AUTOSAR XML (schema 4-3-0)
package /Comp_FDC_ARPkg
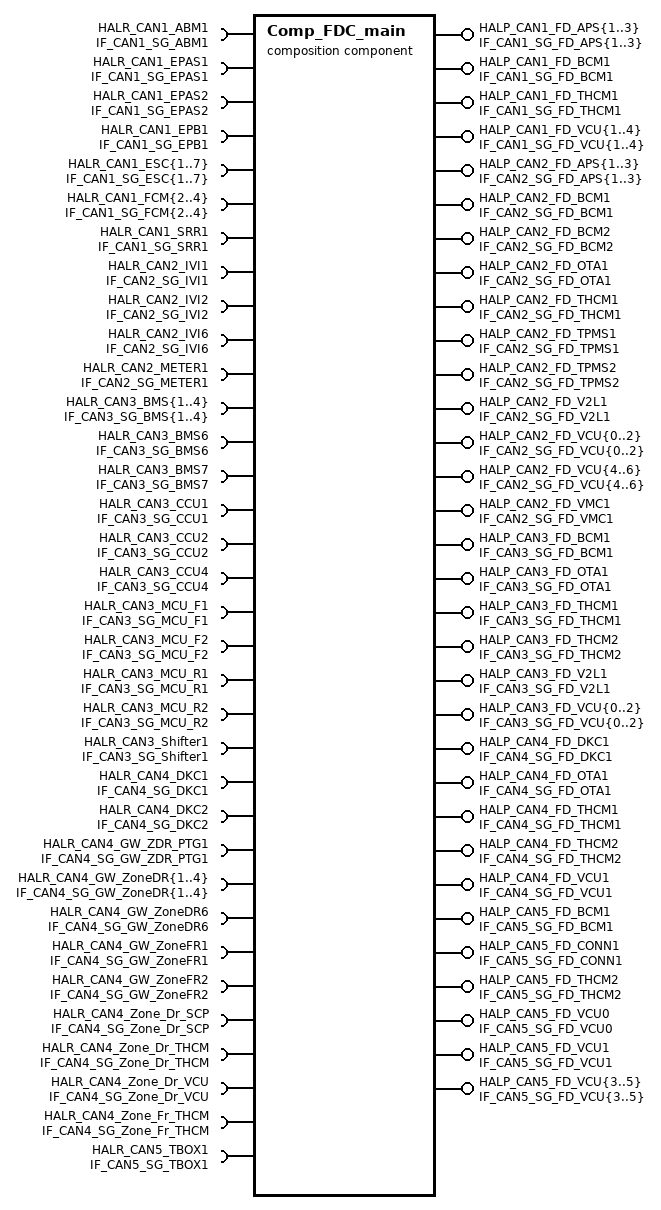
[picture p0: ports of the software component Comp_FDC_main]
  composition sw component type Comp_FDC_main
    47 x provide port:
      HALP_CAN1_FD_APS{1..3}: nonqueued-sender-com-spec{data-element=CAN1_SG_FD_APS{1..3}, handle-out-of-range=DEFAULT, init-value=constant-reference=Init_CAN1_SG_FD_APS{1..3}}, provided-interface=IF_CAN1_SG_FD_APS{1..3}
      HALP_CAN1_FD_BCM1: nonqueued-sender-com-spec{data-element=CAN1_SG_FD_BCM1, handle-out-of-range=DEFAULT, init-value=constant-reference=Init_CAN1_SG_FD_BCM1}, provided-interface=IF_CAN1_SG_FD_BCM1
      HALP_CAN1_FD_THCM1: nonqueued-sender-com-spec{data-element=CAN1_SG_FD_THCM1, handle-out-of-range=DEFAULT, init-value=constant-reference=Init_CAN1_SG_FD_THCM1}, provided-interface=IF_CAN1_SG_FD_THCM1
      HALP_CAN1_FD_VCU{1..4}: nonqueued-sender-com-spec{data-element=CAN1_SG_FD_VCU{1..4}, handle-out-of-range=DEFAULT, init-value=constant-reference=Init_CAN1_SG_FD_VCU{1..4}}, provided-interface=IF_CAN1_SG_FD_VCU{1..4}
      HALP_CAN2_FD_APS{1..3}: nonqueued-sender-com-spec{data-element=CAN2_SG_FD_APS{1..3}, handle-out-of-range=DEFAULT, init-value=constant-reference=Init_CAN2_SG_FD_APS{1..3}}, provided-interface=IF_CAN2_SG_FD_APS{1..3}
      HALP_CAN2_FD_BCM1: nonqueued-sender-com-spec{data-element=CAN2_SG_FD_BCM1, handle-out-of-range=DEFAULT, init-value=constant-reference=Init_CAN2_SG_FD_BCM1}, provided-interface=IF_CAN2_SG_FD_BCM1
      HALP_CAN2_FD_BCM2: nonqueued-sender-com-spec{data-element=CAN2_SG_FD_BCM2, handle-out-of-range=DEFAULT, init-value=constant-reference=Init_CAN2_SG_FD_BCM2}, provided-interface=IF_CAN2_SG_FD_BCM2
      HALP_CAN2_FD_OTA1: nonqueued-sender-com-spec{data-element=CAN2_SG_FD_OTA1, handle-out-of-range=DEFAULT, init-value=constant-reference=Init_CAN2_SG_FD_OTA1}, provided-interface=IF_CAN2_SG_FD_OTA1
      HALP_CAN2_FD_THCM1: nonqueued-sender-com-spec{data-element=CAN2_SG_FD_THCM1, handle-out-of-range=DEFAULT, init-value=constant-reference=Init_CAN2_SG_FD_THCM1}, provided-interface=IF_CAN2_SG_FD_THCM1
      HALP_CAN2_FD_TPMS1: nonqueued-sender-com-spec{data-element=CAN2_SG_FD_TPMS1, handle-out-of-range=DEFAULT, init-value=constant-reference=Init_CAN2_SG_FD_TPMS1}, provided-interface=IF_CAN2_SG_FD_TPMS1
      HALP_CAN2_FD_TPMS2: nonqueued-sender-com-spec{data-element=CAN2_SG_FD_TPMS2, handle-out-of-range=DEFAULT, init-value=constant-reference=Init_CAN2_SG_FD_TPMS2}, provided-interface=IF_CAN2_SG_FD_TPMS2
      HALP_CAN2_FD_V2L1: nonqueued-sender-com-spec{data-element=CAN2_SG_FD_V2L1, handle-out-of-range=DEFAULT, init-value=constant-reference=Init_CAN2_SG_FD_V2L1}, provided-interface=IF_CAN2_SG_FD_V2L1
      HALP_CAN2_FD_VCU{0..2}: nonqueued-sender-com-spec{data-element=CAN2_SG_FD_VCU{0..2}, handle-out-of-range=DEFAULT, init-value=constant-reference=Init_CAN2_SG_FD_VCU{0..2}}, provided-interface=IF_CAN2_SG_FD_VCU{0..2}
      HALP_CAN2_FD_VCU{4..6}: nonqueued-sender-com-spec{data-element=CAN2_SG_FD_VCU{4..6}, handle-out-of-range=DEFAULT, init-value=constant-reference=Init_CAN2_SG_FD_VCU{4..6}}, provided-interface=IF_CAN2_SG_FD_VCU{4..6}
      HALP_CAN2_FD_VMC1: nonqueued-sender-com-spec{data-element=CAN2_SG_FD_VMC1, handle-out-of-range=DEFAULT, init-value=constant-reference=Init_CAN2_SG_FD_VMC1}, provided-interface=IF_CAN2_SG_FD_VMC1
      HALP_CAN3_FD_BCM1: nonqueued-sender-com-spec{data-element=CAN3_SG_FD_BCM1, handle-out-of-range=DEFAULT, init-value=constant-reference=Init_CAN3_SG_FD_BCM1}, provided-interface=IF_CAN3_SG_FD_BCM1
      HALP_CAN3_FD_OTA1: nonqueued-sender-com-spec{data-element=CAN3_SG_FD_OTA1, handle-out-of-range=DEFAULT, init-value=constant-reference=Init_CAN3_SG_FD_OTA1}, provided-interface=IF_CAN3_SG_FD_OTA1
      HALP_CAN3_FD_THCM1: nonqueued-sender-com-spec{data-element=CAN3_SG_FD_THCM1, handle-out-of-range=DEFAULT, init-value=constant-reference=Init_CAN3_SG_FD_THCM1}, provided-interface=IF_CAN3_SG_FD_THCM1
      HALP_CAN3_FD_THCM2: nonqueued-sender-com-spec{data-element=CAN3_SG_FD_THCM2, handle-out-of-range=DEFAULT, init-value=constant-reference=Init_CAN3_SG_FD_THCM2}, provided-interface=IF_CAN3_SG_FD_THCM2
      HALP_CAN3_FD_V2L1: nonqueued-sender-com-spec{data-element=CAN3_SG_FD_V2L1, handle-out-of-range=DEFAULT, init-value=constant-reference=Init_CAN3_SG_FD_V2L1}, provided-interface=IF_CAN3_SG_FD_V2L1
      HALP_CAN3_FD_VCU{0..2}: nonqueued-sender-com-spec{data-element=CAN3_SG_FD_VCU{0..2}, handle-out-of-range=DEFAULT, init-value=constant-reference=Init_CAN3_SG_FD_VCU{0..2}}, provided-interface=IF_CAN3_SG_FD_VCU{0..2}
      HALP_CAN4_FD_DKC1: nonqueued-sender-com-spec{data-element=CAN4_SG_FD_DKC1, handle-out-of-range=DEFAULT, init-value=constant-reference=Init_CAN4_SG_FD_DKC1}, provided-interface=IF_CAN4_SG_FD_DKC1
      HALP_CAN4_FD_OTA1: nonqueued-sender-com-spec{data-element=CAN4_SG_FD_OTA1, handle-out-of-range=DEFAULT, init-value=constant-reference=Init_CAN4_SG_FD_OTA1}, provided-interface=IF_CAN4_SG_FD_OTA1
      HALP_CAN4_FD_THCM1: nonqueued-sender-com-spec{data-element=CAN4_SG_FD_THCM1, handle-out-of-range=DEFAULT, init-value=constant-reference=Init_CAN4_SG_FD_THCM1}, provided-interface=IF_CAN4_SG_FD_THCM1
      HALP_CAN4_FD_THCM2: nonqueued-sender-com-spec{data-element=CAN4_SG_FD_THCM2, handle-out-of-range=DEFAULT, init-value=constant-reference=Init_CAN4_SG_FD_THCM2}, provided-interface=IF_CAN4_SG_FD_THCM2
      HALP_CAN4_FD_VCU1: nonqueued-sender-com-spec{data-element=CAN4_SG_FD_VCU1, handle-out-of-range=DEFAULT, init-value=constant-reference=Init_CAN4_SG_FD_VCU1}, provided-interface=IF_CAN4_SG_FD_VCU1
      HALP_CAN5_FD_BCM1: nonqueued-sender-com-spec{data-element=CAN5_SG_FD_BCM1, handle-out-of-range=DEFAULT, init-value=constant-reference=Init_CAN5_SG_FD_BCM1}, provided-interface=IF_CAN5_SG_FD_BCM1
      HALP_CAN5_FD_CONN1: nonqueued-sender-com-spec{data-element=CAN5_SG_FD_CONN1, handle-out-of-range=DEFAULT, init-value=constant-reference=Init_CAN5_SG_FD_CONN1}, provided-interface=IF_CAN5_SG_FD_CONN1
      HALP_CAN5_FD_THCM2: nonqueued-sender-com-spec{data-element=CAN5_SG_FD_THCM2, handle-out-of-range=DEFAULT, init-value=constant-reference=Init_CAN5_SG_FD_THCM2}, provided-interface=IF_CAN5_SG_FD_THCM2
      HALP_CAN5_FD_VCU0: nonqueued-sender-com-spec{data-element=CAN5_SG_FD_VCU0, handle-out-of-range=DEFAULT, init-value=constant-reference=Init_CAN5_SG_FD_VCU0}, provided-interface=IF_CAN5_SG_FD_VCU0
      HALP_CAN5_FD_VCU1: nonqueued-sender-com-spec{data-element=CAN5_SG_FD_VCU1, handle-out-of-range=DEFAULT, init-value=constant-reference=Init_CAN5_SG_FD_VCU1}, provided-interface=IF_CAN5_SG_FD_VCU1
      HALP_CAN5_FD_VCU{3..5}: nonqueued-sender-com-spec{data-element=CAN5_SG_FD_VCU{3..5}, handle-out-of-range=DEFAULT, init-value=constant-reference=Init_CAN5_SG_FD_VCU{3..5}}, provided-interface=IF_CAN5_SG_FD_VCU{3..5}
    48 x require port:
      HALR_CAN1_ABM1: nonqueued-receiver-com-spec{data-element=CAN1_SG_ABM1, handle-out-of-range=DEFAULT, enable-update=true, init-value=constant-reference=Init_CAN1_SG_ABM1}, required-interface=IF_CAN1_SG_ABM1
      HALR_CAN1_EPAS1: nonqueued-receiver-com-spec{data-element=CAN1_SG_EPAS1, handle-out-of-range=DEFAULT, enable-update=true, init-value=constant-reference=Init_CAN1_SG_EPAS1}, required-interface=IF_CAN1_SG_EPAS1
      HALR_CAN1_EPAS2: nonqueued-receiver-com-spec{data-element=CAN1_SG_EPAS2, handle-out-of-range=DEFAULT, enable-update=true, init-value=constant-reference=Init_CAN1_SG_EPAS2}, required-interface=IF_CAN1_SG_EPAS2
      HALR_CAN1_EPB1: nonqueued-receiver-com-spec{data-element=CAN1_SG_EPB1, handle-out-of-range=DEFAULT, enable-update=true, init-value=constant-reference=Init_CAN1_SG_EPB1}, required-interface=IF_CAN1_SG_EPB1
      HALR_CAN1_ESC{1..7}: nonqueued-receiver-com-spec{data-element=CAN1_SG_ESC{1..7}, handle-out-of-range=DEFAULT, enable-update=true, init-value=constant-reference=Init_CAN1_SG_ESC{1..7}}, required-interface=IF_CAN1_SG_ESC{1..7}
      HALR_CAN1_FCM{2..4}: nonqueued-receiver-com-spec{data-element=CAN1_SG_FCM{2..4}, handle-out-of-range=DEFAULT, enable-update=true, init-value=constant-reference=Init_CAN1_SG_FCM{2..4}}, required-interface=IF_CAN1_SG_FCM{2..4}
      HALR_CAN1_SRR1: nonqueued-receiver-com-spec{data-element=CAN1_SG_SRR1, handle-out-of-range=DEFAULT, enable-update=true, init-value=constant-reference=Init_CAN1_SG_SRR1}, required-interface=IF_CAN1_SG_SRR1
      HALR_CAN2_IVI1: nonqueued-receiver-com-spec{data-element=CAN2_SG_IVI1, handle-out-of-range=DEFAULT, enable-update=true, init-value=constant-reference=Init_CAN2_SG_IVI1}, required-interface=IF_CAN2_SG_IVI1
      HALR_CAN2_IVI2: nonqueued-receiver-com-spec{data-element=CAN2_SG_IVI2, handle-out-of-range=DEFAULT, enable-update=true, init-value=constant-reference=Init_CAN2_SG_IVI2}, required-interface=IF_CAN2_SG_IVI2
      HALR_CAN2_IVI6: nonqueued-receiver-com-spec{data-element=CAN2_SG_IVI6, handle-out-of-range=DEFAULT, enable-update=true, init-value=constant-reference=Init_CAN2_SG_IVI6}, required-interface=IF_CAN2_SG_IVI6
      HALR_CAN2_METER1: nonqueued-receiver-com-spec{data-element=CAN2_SG_METER1, handle-out-of-range=DEFAULT, enable-update=true, init-value=constant-reference=Init_CAN2_SG_METER1}, required-interface=IF_CAN2_SG_METER1
      HALR_CAN3_BMS{1..4}: nonqueued-receiver-com-spec{data-element=CAN3_SG_BMS{1..4}, handle-out-of-range=DEFAULT, enable-update=true, init-value=constant-reference=Init_CAN3_SG_BMS{1..4}}, required-interface=IF_CAN3_SG_BMS{1..4}
      HALR_CAN3_BMS6: nonqueued-receiver-com-spec{data-element=CAN3_SG_BMS6, handle-out-of-range=DEFAULT, enable-update=true, init-value=constant-reference=Init_CAN3_SG_BMS6}, required-interface=IF_CAN3_SG_BMS6
      HALR_CAN3_BMS7: nonqueued-receiver-com-spec{data-element=CAN3_SG_BMS7, handle-out-of-range=DEFAULT, enable-update=true, init-value=constant-reference=Init_CAN3_SG_BMS7}, required-interface=IF_CAN3_SG_BMS7
      HALR_CAN3_CCU1: nonqueued-receiver-com-spec{data-element=CAN3_SG_CCU1, handle-out-of-range=DEFAULT, enable-update=true, init-value=constant-reference=Init_CAN3_SG_CCU1}, required-interface=IF_CAN3_SG_CCU1
      HALR_CAN3_CCU2: nonqueued-receiver-com-spec{data-element=CAN3_SG_CCU2, handle-out-of-range=DEFAULT, enable-update=true, init-value=constant-reference=Init_CAN3_SG_CCU2}, required-interface=IF_CAN3_SG_CCU2
      HALR_CAN3_CCU4: nonqueued-receiver-com-spec{data-element=CAN3_SG_CCU4, handle-out-of-range=DEFAULT, enable-update=true, init-value=constant-reference=Init_CAN3_SG_CCU4}, required-interface=IF_CAN3_SG_CCU4
      HALR_CAN3_MCU_F1: nonqueued-receiver-com-spec{data-element=CAN3_SG_MCU_F1, handle-out-of-range=DEFAULT, enable-update=true, init-value=constant-reference=Init_CAN3_SG_MCU_F1}, required-interface=IF_CAN3_SG_MCU_F1
      HALR_CAN3_MCU_F2: nonqueued-receiver-com-spec{data-element=CAN3_SG_MCU_F2, handle-out-of-range=DEFAULT, enable-update=true, init-value=constant-reference=Init_CAN3_SG_MCU_F2}, required-interface=IF_CAN3_SG_MCU_F2
      HALR_CAN3_MCU_R1: nonqueued-receiver-com-spec{data-element=CAN3_SG_MCU_R1, handle-out-of-range=DEFAULT, enable-update=true, init-value=constant-reference=Init_CAN3_SG_MCU_R1}, required-interface=IF_CAN3_SG_MCU_R1
      HALR_CAN3_MCU_R2: nonqueued-receiver-com-spec{data-element=CAN3_SG_MCU_R2, handle-out-of-range=DEFAULT, enable-update=true, init-value=constant-reference=Init_CAN3_SG_MCU_R2}, required-interface=IF_CAN3_SG_MCU_R2
      HALR_CAN3_Shifter1: nonqueued-receiver-com-spec{data-element=CAN3_SG_Shifter1, handle-out-of-range=DEFAULT, enable-update=true, init-value=constant-reference=Init_CAN3_SG_Shifter1}, required-interface=IF_CAN3_SG_Shifter1
      HALR_CAN4_DKC1: nonqueued-receiver-com-spec{data-element=CAN4_SG_DKC1, handle-out-of-range=DEFAULT, enable-update=true, init-value=constant-reference=Init_CAN4_SG_DKC1}, required-interface=IF_CAN4_SG_DKC1
      HALR_CAN4_DKC2: nonqueued-receiver-com-spec{data-element=CAN4_SG_DKC2, handle-out-of-range=DEFAULT, enable-update=true, init-value=constant-reference=Init_CAN4_SG_DKC2}, required-interface=IF_CAN4_SG_DKC2
      HALR_CAN4_GW_ZDR_PTG1: nonqueued-receiver-com-spec{data-element=CAN4_SG_GW_ZDR_PTG1, handle-out-of-range=DEFAULT, enable-update=true, init-value=constant-reference=Init_CAN4_SG_GW_ZDR_PTG1}, required-interface=IF_CAN4_SG_GW_ZDR_PTG1
      HALR_CAN4_GW_ZoneDR{1..4}: nonqueued-receiver-com-spec{data-element=CAN4_SG_GW_ZoneDR{1..4}, handle-out-of-range=DEFAULT, enable-update=true, init-value=constant-reference=Init_CAN4_SG_GW_ZoneDR{1..4}}, required-interface=IF_CAN4_SG_GW_ZoneDR{1..4}
      HALR_CAN4_GW_ZoneDR6: nonqueued-receiver-com-spec{data-element=CAN4_SG_GW_ZoneDR6, handle-out-of-range=DEFAULT, enable-update=true, init-value=constant-reference=Init_CAN4_SG_GW_ZoneDR6}, required-interface=IF_CAN4_SG_GW_ZoneDR6
      HALR_CAN4_GW_ZoneFR1: nonqueued-receiver-com-spec{data-element=CAN4_SG_GW_ZoneFR1, handle-out-of-range=DEFAULT, enable-update=true, init-value=constant-reference=Init_CAN4_SG_GW_ZoneFR1}, required-interface=IF_CAN4_SG_GW_ZoneFR1
      HALR_CAN4_GW_ZoneFR2: nonqueued-receiver-com-spec{data-element=CAN4_SG_GW_ZoneFR2, handle-out-of-range=DEFAULT, enable-update=true, init-value=constant-reference=Init_CAN4_SG_GW_ZoneFR2}, required-interface=IF_CAN4_SG_GW_ZoneFR2
      HALR_CAN4_Zone_Dr_SCP: nonqueued-receiver-com-spec{data-element=CAN4_SG_Zone_Dr_SCP, handle-out-of-range=DEFAULT, enable-update=true, init-value=constant-reference=Init_CAN4_SG_Zone_Dr_SCP}, required-interface=IF_CAN4_SG_Zone_Dr_SCP
      HALR_CAN4_Zone_Dr_THCM: nonqueued-receiver-com-spec{data-element=CAN4_SG_Zone_Dr_THCM, handle-out-of-range=DEFAULT, enable-update=true, init-value=constant-reference=Init_CAN4_SG_Zone_Dr_THCM}, required-interface=IF_CAN4_SG_Zone_Dr_THCM
      HALR_CAN4_Zone_Dr_VCU: nonqueued-receiver-com-spec{data-element=CAN4_SG_Zone_Dr_VCU, handle-out-of-range=DEFAULT, enable-update=true, init-value=constant-reference=Init_CAN4_SG_Zone_Dr_VCU}, required-interface=IF_CAN4_SG_Zone_Dr_VCU
      HALR_CAN4_Zone_Fr_THCM: nonqueued-receiver-com-spec{data-element=CAN4_SG_Zone_Fr_THCM, handle-out-of-range=DEFAULT, enable-update=true, init-value=constant-reference=Init_CAN4_SG_Zone_Fr_THCM}, required-interface=IF_CAN4_SG_Zone_Fr_THCM
      HALR_CAN5_TBOX1: nonqueued-receiver-com-spec{data-element=CAN5_SG_TBOX1, handle-out-of-range=DEFAULT, enable-update=true, init-value=constant-reference=Init_CAN5_SG_TBOX1}, required-interface=IF_CAN5_SG_TBOX1
    11 x component:
      BswMTest: type=BswMTest_type
      SWC_APS: type=SWC_APS_type
      SWC_CDD: type=SWC_CDD_type
      SWC_DID: type=SWC_DID_type
      SWC_FDC: type=SWC_FDC_type
      SWC_IMU: type=SWC_IMU_type
      SWC_LOG: type=SWC_LOG_type
      SWC_NVM: type=SWC_NVM_type
      SWC_UART: type=SWC_UART_type
      SWC_UDS: type=SWC_UDS_type
      SWC_VES: type=SWC_VES_type
    delegate SWC_FDC.R_CAN1_ABM1 <-> outer port HALR_CAN1_ABM1
    delegate SWC_FDC.R_CAN1_EPAS1 <-> outer port HALR_CAN1_EPAS1
    delegate SWC_FDC.R_CAN1_EPAS2 <-> outer port HALR_CAN1_EPAS2
    delegate SWC_FDC.R_CAN1_EPB1 <-> outer port HALR_CAN1_EPB1
    delegate SWC_FDC.R_CAN1_ESC{1..7} <-> outer port HALR_CAN1_ESC{1..7}
    delegate SWC_FDC.R_CAN1_FCM{2..4} <-> outer port HALR_CAN1_FCM{2..4}
    delegate SWC_FDC.P_CAN1_FD_APS{1..3} <-> outer port HALP_CAN1_FD_APS{1..3}
    delegate SWC_FDC.P_CAN1_FD_BCM1 <-> outer port HALP_CAN1_FD_BCM1
    delegate SWC_FDC.P_CAN1_FD_THCM1 <-> outer port HALP_CAN1_FD_THCM1
    delegate SWC_FDC.P_CAN1_FD_VCU{1..4} <-> outer port HALP_CAN1_FD_VCU{1..4}
    delegate SWC_FDC.R_CAN1_SRR1 <-> outer port HALR_CAN1_SRR1
    delegate SWC_FDC.P_CAN2_FD_APS{1..3} <-> outer port HALP_CAN2_FD_APS{1..3}
    delegate SWC_FDC.P_CAN2_FD_BCM1 <-> outer port HALP_CAN2_FD_BCM1
    delegate SWC_FDC.P_CAN2_FD_BCM2 <-> outer port HALP_CAN2_FD_BCM2
    delegate SWC_VES.P_CAN2_FD_OTA1 <-> outer port HALP_CAN2_FD_OTA1
    delegate SWC_FDC.P_CAN2_FD_THCM1 <-> outer port HALP_CAN2_FD_THCM1
    delegate SWC_FDC.P_CAN2_FD_TPMS1 <-> outer port HALP_CAN2_FD_TPMS1
    delegate SWC_FDC.P_CAN2_FD_TPMS2 <-> outer port HALP_CAN2_FD_TPMS2
    delegate SWC_FDC.P_CAN2_FD_V2L1 <-> outer port HALP_CAN2_FD_V2L1
    delegate SWC_FDC.P_CAN2_FD_VCU{0..2} <-> outer port HALP_CAN2_FD_VCU{0..2}
    delegate SWC_FDC.P_CAN2_FD_VCU{4..6} <-> outer port HALP_CAN2_FD_VCU{4..6}
    delegate SWC_FDC.P_CAN2_FD_VMC1 <-> outer port HALP_CAN2_FD_VMC1
    delegate SWC_FDC.R_CAN2_IVI1 <-> outer port HALR_CAN2_IVI1
    delegate SWC_FDC.R_CAN2_IVI2 <-> outer port HALR_CAN2_IVI2
    delegate SWC_FDC.R_CAN2_IVI6 <-> outer port HALR_CAN2_IVI6
    delegate SWC_FDC.R_CAN2_METER1 <-> outer port HALR_CAN2_METER1
    delegate SWC_FDC.R_CAN3_BMS{1..4} <-> outer port HALR_CAN3_BMS{1..4}
    delegate SWC_FDC.R_CAN3_BMS6 <-> outer port HALR_CAN3_BMS6
    delegate SWC_FDC.R_CAN3_BMS7 <-> outer port HALR_CAN3_BMS7
    delegate SWC_FDC.R_CAN3_CCU1 <-> outer port HALR_CAN3_CCU1
    delegate SWC_FDC.R_CAN3_CCU2 <-> outer port HALR_CAN3_CCU2
    delegate SWC_FDC.R_CAN3_CCU4 <-> outer port HALR_CAN3_CCU4
    delegate SWC_FDC.P_CAN3_FD_BCM1 <-> outer port HALP_CAN3_FD_BCM1
    delegate SWC_VES.P_CAN3_FD_OTA1 <-> outer port HALP_CAN3_FD_OTA1
    delegate SWC_FDC.P_CAN3_FD_THCM1 <-> outer port HALP_CAN3_FD_THCM1
    delegate SWC_FDC.P_CAN3_FD_THCM2 <-> outer port HALP_CAN3_FD_THCM2
    delegate SWC_FDC.P_CAN3_FD_V2L1 <-> outer port HALP_CAN3_FD_V2L1
    delegate SWC_FDC.P_CAN3_FD_VCU{0..2} <-> outer port HALP_CAN3_FD_VCU{0..2}
    delegate SWC_FDC.R_CAN3_MCU_F1 <-> outer port HALR_CAN3_MCU_F1
    delegate SWC_FDC.R_CAN3_MCU_F2 <-> outer port HALR_CAN3_MCU_F2
    delegate SWC_FDC.R_CAN3_MCU_R1 <-> outer port HALR_CAN3_MCU_R1
    delegate SWC_FDC.R_CAN3_MCU_R2 <-> outer port HALR_CAN3_MCU_R2
    delegate SWC_FDC.R_CAN3_Shifter1 <-> outer port HALR_CAN3_Shifter1
    delegate SWC_FDC.R_CAN4_DKC1 <-> outer port HALR_CAN4_DKC1
    delegate SWC_FDC.R_CAN4_DKC2 <-> outer port HALR_CAN4_DKC2
    delegate SWC_FDC.P_CAN4_FD_DKC1 <-> outer port HALP_CAN4_FD_DKC1
    delegate SWC_VES.P_CAN4_FD_OTA1 <-> outer port HALP_CAN4_FD_OTA1
    delegate SWC_FDC.P_CAN4_FD_THCM1 <-> outer port HALP_CAN4_FD_THCM1
    delegate SWC_FDC.P_CAN4_FD_THCM2 <-> outer port HALP_CAN4_FD_THCM2
    delegate SWC_FDC.P_CAN4_FD_VCU1 <-> outer port HALP_CAN4_FD_VCU1
    delegate SWC_FDC.R_CAN4_GW_ZDR_PTG1 <-> outer port HALR_CAN4_GW_ZDR_PTG1
    delegate SWC_FDC.R_CAN4_GW_ZoneDR{1..4} <-> outer port HALR_CAN4_GW_ZoneDR{1..4}
    delegate SWC_FDC.R_CAN4_GW_ZoneDR6 <-> outer port HALR_CAN4_GW_ZoneDR6
    delegate SWC_FDC.R_CAN4_GW_ZoneFR1 <-> outer port HALR_CAN4_GW_ZoneFR1
    delegate SWC_FDC.R_CAN4_GW_ZoneFR2 <-> outer port HALR_CAN4_GW_ZoneFR2
    delegate SWC_FDC.R_CAN4_Zone_Dr_SCP <-> outer port HALR_CAN4_Zone_Dr_SCP
    delegate SWC_FDC.R_CAN4_Zone_Dr_THCM <-> outer port HALR_CAN4_Zone_Dr_THCM
    delegate SWC_FDC.R_CAN4_Zone_Dr_VCU <-> outer port HALR_CAN4_Zone_Dr_VCU
    delegate SWC_FDC.R_CAN4_Zone_Fr_THCM <-> outer port HALR_CAN4_Zone_Fr_THCM
    delegate SWC_FDC.P_CAN5_FD_BCM1 <-> outer port HALP_CAN5_FD_BCM1
    delegate SWC_FDC.P_CAN5_FD_CONN1 <-> outer port HALP_CAN5_FD_CONN1
    delegate SWC_FDC.P_CAN5_FD_THCM2 <-> outer port HALP_CAN5_FD_THCM2
    delegate SWC_FDC.P_CAN5_FD_VCU0 <-> outer port HALP_CAN5_FD_VCU0
    delegate SWC_FDC.P_CAN5_FD_VCU1 <-> outer port HALP_CAN5_FD_VCU1
    delegate SWC_FDC.P_CAN5_FD_VCU{3..5} <-> outer port HALP_CAN5_FD_VCU{3..5}
    delegate SWC_FDC.R_CAN5_TBOX1 <-> outer port HALR_CAN5_TBOX1
    connect SWC_APS.P_HALINCDD_APS -> SWC_FDC.R_HALIN_APS
    connect SWC_APS.P_HALOUTCDD_APS -> SWC_FDC.R_HALOUT_APS
    connect SWC_CDD.P_HALINCDD -> SWC_FDC.R_HALINCDD
    connect SWC_CDD.P_HALINCDD -> SWC_VES.R_HALINCDD
    connect SWC_CDD.P_HALOUTCDD -> SWC_FDC.R_HALOUTCDD
    connect SWC_DID.P_DIDReadCDD -> SWC_FDC.R_DIDReadCDD
    connect SWC_DID.P_DIDWriteCDD -> SWC_FDC.R_DIDWriteCDD
    connect SWC_FDC.P_AppModeReq -> BswMTest.R_AppModeReq
    connect SWC_FDC.P_E2E_CAN3_VCU1 -> SWC_FDC.R_E2E_CAN3_VCU1
    connect SWC_FDC.P_E2E_CAN4_VCU1 -> SWC_FDC.R_E2E_CAN4_VCU1
    connect SWC_FDC.P_FDCDD_Inner -> SWC_FDC.R_FDCCDD_Inner
    connect SWC_FDC.P_NVMReadCDD_Inner -> SWC_FDC.R_NVMReadCDD_Inner
    connect SWC_FDC.P_NVMWriteCDD_Inner -> SWC_FDC.R_NVMWriteCDD_Inner
    connect SWC_FDC.P_NVMWrite -> SWC_NVM.R_WriteNVData
    connect SWC_FDC.P_WDGCDD -> SWC_FDC.R_WDGCDD
    connect SWC_IMU.P_HAINICDD_IMU -> SWC_FDC.R_HALIN_IMU
    connect SWC_NVM.P_ReadNVData -> SWC_FDC.R_NVMRead
    connect SWC_UART.P_UARTCDD -> SWC_UART.R_UARTCDD
    connect SWC_UDS.P_UDSCDD -> SWC_FDC.R_UDSCDD
    connect SWC_VES.P_VESCDD -> SWC_VES.R_VESCDD
